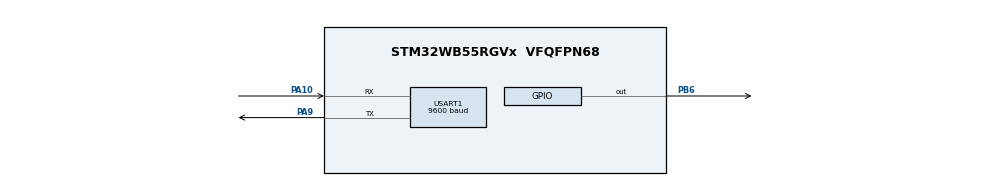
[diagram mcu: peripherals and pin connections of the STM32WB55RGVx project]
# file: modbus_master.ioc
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Mcu.Family=STM32WB
Mcu.Name=STM32WB55RGVx
Mcu.Package=VFQFPN68
NVIC.PriorityGroup=NVIC_PRIORITYGROUP_4
NVIC.TIM2_IRQn=true\:0\:0\:false\:false\:true\:true\:true\:true
NVIC.USART1_IRQn=true\:0\:0\:false\:false\:true\:true\:true\:true
OSC_IN.Mode=HSE-External-Oscillator
OSC_IN.Signal=RCC_OSC_IN
OSC_OUT.Mode=HSE-External-Oscillator
OSC_OUT.Signal=RCC_OSC_OUT
PA10.Mode=Asynchronous
PA10.Signal=USART1_RX
PA9.Mode=Asynchronous
PA9.Signal=USART1_TX
PB6.Signal=GPIO_Output
ProjectManager.HeapSize=0x200
ProjectManager.StackSize=0x400
ProjectManager.TargetToolchain=STM32CubeIDE
RCC.ADCFreq_Value=16000000
RCC.AHBFreq_Value=4000000
RCC.APB1Freq_Value=4000000
RCC.APB1TimFreq_Value=4000000
RCC.APB2Freq_Value=4000000
RCC.APB2TimFreq_Value=4000000
RCC.APB3Freq_Value=4000000
RCC.CortexFreq_Value=4000000
RCC.HCLKFreq_Value=4000000
RCC.HSE_VALUE=8000000
RCC.HSI48_VALUE=48000000
RCC.HSI_VALUE=16000000
RCC.LSE_VALUE=32768
RCC.SYSCLKFreq_VALUE=4000000
RCC.USBFreq_Value=16000000
RCC.VCOOutputFreq_Value=32000000
TIM2.Period=9999
TIM2.Prescaler=399
USART1.BaudRate=9600
USART1.VirtualMode-Asynchronous=VM_ASYNC
VP_MEMORYMAP_VS_MEMORYMAP.Mode=CurAppReg
VP_TIM2_VS_ClockSourceINT.Mode=Internal
board=custom

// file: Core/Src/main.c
/* USER CODE BEGIN Header */
/**
  ******************************************************************************
  * @file           : main.c
  * @brief          : Main program body
  ******************************************************************************
  * @attention
  *
  * Copyright (c) 2025 STMicroelectronics.
  * All rights reserved.
  *
  * This software is licensed under terms that can be found in the LICENSE file
  * in the root directory of this software component.
  * If no LICENSE file comes with this software, it is provided AS-IS.
  *
  ******************************************************************************
  */
/* USER CODE END Header */
#include "main.h"
#include "ModbusMS.h"

TIM_HandleTypeDef htim2;

UART_HandleTypeDef huart1;

void SystemClock_Config(void);
void PeriphCommonClock_Config(void);
static void MX_GPIO_Init(void);
static void MX_USART1_UART_Init(void);
static void MX_TIM2_Init(void);

/* USER CODE BEGIN 0 */

void ModbusMasterRxCpltCallback(void)
{
    if (gModbusMasterData.rxPointer < gModbusMasterData.totalRxValue)

        gModbusMasterData.modbusFrame[gModbusMasterData.rxPointer++] = gRxBuffer[0];

    if (gModbusMasterData.rxPointer == gModbusMasterData.totalRxValue)
    {
        ModbusMasterProcessReceivedResponse();

        if (gModbusMasterData.flags.bitValue.processSuccess)

            gTXCounter++;

    }

        HAL_UART_Receive_IT(&huart1, gRxBuffer, 11);

}

//1.send modbus frame every 1 second
void HAL_TIM_PeriodElapsedCallback(TIM_HandleTypeDef* htim)
{
    if (htim->Instance == TIM2)
    {

           TransmitModbusMaster();
           HAL_UART_Transmit_IT(&huart1, gModbusMasterData.modbusFrame, gModbusMasterData.totalTxValue);

    }
}

//void HAL_UART_TxCpltCallback(UART_HandleTypeDef *huart)
//{
//    if (huart->Instance == USART1)
//    {
//        // Transmission done, clear busy flag
//        gModbusMasterData.flags.bitValue.busyProcessing = 0;
//
//        // Start reception for response
//        HAL_UART_Receive_IT(&huart1, gRxBuffer, 11);
//    }
//}

/* USER CODE END 0 */

int main(void)
{

  /* MCU Configuration--------------------------------------------------------*/

  /* Reset of all peripherals, Initializes the Flash interface and the Systick. */
  HAL_Init();

  /* Configure the system clock */
  SystemClock_Config();

  /* Configure the peripherals common clocks */
  PeriphCommonClock_Config();

  /* Initialize all configured peripherals */
  MX_GPIO_Init();
  MX_USART1_UART_Init();
  MX_TIM2_Init();
  ModbusInit();
  /* USER CODE BEGIN 2 */
  HAL_TIM_Base_Start_IT(&htim2);
  HAL_UART_Receive_IT(&huart1, gRxBuffer, 11);

  /* USER CODE END 2 */

  /* Infinite loop */
  while (1)
  {

  }
}

void SystemClock_Config(void)
{
  RCC_OscInitTypeDef RCC_OscInitStruct = {0};
  RCC_ClkInitTypeDef RCC_ClkInitStruct = {0};

  /** Configure the main internal regulator output voltage
  */
  __HAL_PWR_VOLTAGESCALING_CONFIG(PWR_REGULATOR_VOLTAGE_SCALE1);

  /** Initializes the RCC Oscillators according to the specified parameters
  * in the RCC_OscInitTypeDef structure.
  */
  RCC_OscInitStruct.OscillatorType = RCC_OSCILLATORTYPE_HSI|RCC_OSCILLATORTYPE_HSE
                              |RCC_OSCILLATORTYPE_MSI;
  RCC_OscInitStruct.HSEState = RCC_HSE_ON;
  RCC_OscInitStruct.HSIState = RCC_HSI_ON;
  RCC_OscInitStruct.MSIState = RCC_MSI_ON;
  RCC_OscInitStruct.HSICalibrationValue = RCC_HSICALIBRATION_DEFAULT;
  RCC_OscInitStruct.MSICalibrationValue = RCC_MSICALIBRATION_DEFAULT;
  RCC_OscInitStruct.MSIClockRange = RCC_MSIRANGE_6;
  RCC_OscInitStruct.PLL.PLLState = RCC_PLL_NONE;
  if (HAL_RCC_OscConfig(&RCC_OscInitStruct) != HAL_OK)
  {
    Error_Handler();
  }

  /** Configure the SYSCLKSource, HCLK, PCLK1 and PCLK2 clocks dividers
  */
  RCC_ClkInitStruct.ClockType = RCC_CLOCKTYPE_HCLK4|RCC_CLOCKTYPE_HCLK2
                              |RCC_CLOCKTYPE_HCLK|RCC_CLOCKTYPE_SYSCLK
                              |RCC_CLOCKTYPE_PCLK1|RCC_CLOCKTYPE_PCLK2;
  RCC_ClkInitStruct.SYSCLKSource = RCC_SYSCLKSOURCE_MSI;
  RCC_ClkInitStruct.AHBCLKDivider = RCC_SYSCLK_DIV1;
  RCC_ClkInitStruct.APB1CLKDivider = RCC_HCLK_DIV1;
  RCC_ClkInitStruct.APB2CLKDivider = RCC_HCLK_DIV1;
  RCC_ClkInitStruct.AHBCLK2Divider = RCC_SYSCLK_DIV1;
  RCC_ClkInitStruct.AHBCLK4Divider = RCC_SYSCLK_DIV1;

  if (HAL_RCC_ClockConfig(&RCC_ClkInitStruct, FLASH_LATENCY_0) != HAL_OK)
  {
    Error_Handler();
  }
}

void PeriphCommonClock_Config(void)
{
  RCC_PeriphCLKInitTypeDef PeriphClkInitStruct = {0};

  /** Initializes the peripherals clock
  */
  PeriphClkInitStruct.PeriphClockSelection = RCC_PERIPHCLK_SMPS;
  PeriphClkInitStruct.SmpsClockSelection = RCC_SMPSCLKSOURCE_HSI;
  PeriphClkInitStruct.SmpsDivSelection = RCC_SMPSCLKDIV_RANGE1;

  if (HAL_RCCEx_PeriphCLKConfig(&PeriphClkInitStruct) != HAL_OK)
  {
    Error_Handler();
  }
}

static void MX_TIM2_Init(void)
{

  TIM_ClockConfigTypeDef sClockSourceConfig = {0};
  TIM_MasterConfigTypeDef sMasterConfig = {0};

  htim2.Instance = TIM2;
  htim2.Init.Prescaler = 399;
  htim2.Init.CounterMode = TIM_COUNTERMODE_UP;
  htim2.Init.Period = 39999;
  htim2.Init.ClockDivision = TIM_CLOCKDIVISION_DIV1;
  htim2.Init.AutoReloadPreload = TIM_AUTORELOAD_PRELOAD_DISABLE;
  if (HAL_TIM_Base_Init(&htim2) != HAL_OK)
  {
    Error_Handler();
  }
  sClockSourceConfig.ClockSource = TIM_CLOCKSOURCE_INTERNAL;
  if (HAL_TIM_ConfigClockSource(&htim2, &sClockSourceConfig) != HAL_OK)
  {
    Error_Handler();
  }
  sMasterConfig.MasterOutputTrigger = TIM_TRGO_RESET;
  sMasterConfig.MasterSlaveMode = TIM_MASTERSLAVEMODE_DISABLE;
  if (HAL_TIMEx_MasterConfigSynchronization(&htim2, &sMasterConfig) != HAL_OK)
  {
    Error_Handler();
  }

}

static void MX_USART1_UART_Init(void)
{

  huart1.Instance = USART1;
  huart1.Init.BaudRate = 9600;
  huart1.Init.WordLength = UART_WORDLENGTH_8B;
  huart1.Init.StopBits = UART_STOPBITS_1;
  huart1.Init.Parity = UART_PARITY_NONE;
  huart1.Init.Mode = UART_MODE_TX_RX;
  huart1.Init.HwFlowCtl = UART_HWCONTROL_NONE;
  huart1.Init.OverSampling = UART_OVERSAMPLING_16;
  huart1.Init.OneBitSampling = UART_ONE_BIT_SAMPLE_DISABLE;
  huart1.Init.ClockPrescaler = UART_PRESCALER_DIV1;
  huart1.AdvancedInit.AdvFeatureInit = UART_ADVFEATURE_NO_INIT;
  if (HAL_UART_Init(&huart1) != HAL_OK)
  {
    Error_Handler();
  }
  if (HAL_UARTEx_SetTxFifoThreshold(&huart1, UART_TXFIFO_THRESHOLD_1_8) != HAL_OK)
  {
    Error_Handler();
  }
  if (HAL_UARTEx_SetRxFifoThreshold(&huart1, UART_RXFIFO_THRESHOLD_1_8) != HAL_OK)
  {
    Error_Handler();
  }
  if (HAL_UARTEx_DisableFifoMode(&huart1) != HAL_OK)
  {
    Error_Handler();
  }

}

static void MX_GPIO_Init(void)
{
  GPIO_InitTypeDef GPIO_InitStruct = {0};

  /* GPIO Ports Clock Enable */
  __HAL_RCC_GPIOA_CLK_ENABLE();
  __HAL_RCC_GPIOB_CLK_ENABLE();

  /*Configure GPIO pin Output Level */
  HAL_GPIO_WritePin(GPIOB, GPIO_PIN_6, GPIO_PIN_RESET);

  /*Configure GPIO pin : PB6 */
  GPIO_InitStruct.Pin = GPIO_PIN_6;
  GPIO_InitStruct.Mode = GPIO_MODE_OUTPUT_PP;
  GPIO_InitStruct.Pull = GPIO_NOPULL;
  GPIO_InitStruct.Speed = GPIO_SPEED_FREQ_LOW;
  HAL_GPIO_Init(GPIOB, &GPIO_InitStruct);

}

void Error_Handler(void)
{
  __disable_irq();
  while (1)
  {
  }
}
